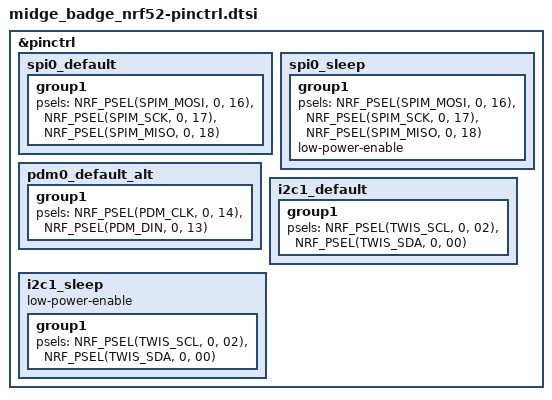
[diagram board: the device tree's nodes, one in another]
&pinctrl {
	spi0_default: spi0_default {
		group1 {
			psels = <NRF_PSEL(SPIM_MOSI, 0, 16)>, <NRF_PSEL(SPIM_SCK, 0, 17)>, <NRF_PSEL(SPIM_MISO, 0, 18)>;
		};
	};

	spi0_sleep: spi0_sleep {
		group1 {
			psels = <NRF_PSEL(SPIM_MOSI, 0, 16)>, <NRF_PSEL(SPIM_SCK, 0, 17)>,<NRF_PSEL(SPIM_MISO, 0, 18)>;
			low-power-enable;
		};
	};

	pdm0_default_alt: pdm0_default_alt {
		group1 {
			psels = <NRF_PSEL(PDM_CLK, 0, 14)>,
				<NRF_PSEL(PDM_DIN, 0, 13)>;
		};
	};

	i2c1_default: i2c1_default {
		group1 {
			psels = <NRF_PSEL(TWIS_SCL, 0, 02)>, <NRF_PSEL(TWIS_SDA, 0, 00)>;
		};
	};

	i2c1_sleep: i2c1_sleep {
		group1 {
			psels = <NRF_PSEL(TWIS_SCL, 0, 02)>, <NRF_PSEL(TWIS_SDA, 0, 00)>;
		};
		low-power-enable;
	};
};
